# STM32F40x register map
File version: 1.5
Registers are 32-bit, read-write, reset 0x0 unless marked. A register's access mark holds for its fields unless they carry their own. Offsets are from the block's base; [hi:lo] are bit positions; {n}, {i} and the like mark numbered series; 'fields as' and 'values as' point back to an identical list.

## OTG_HS_HOST（USB_OTG_HS_主机寄存器） — USB OTG HS 主机寄存器（best-effort） | USB on the go high speed
Base 0x40040400
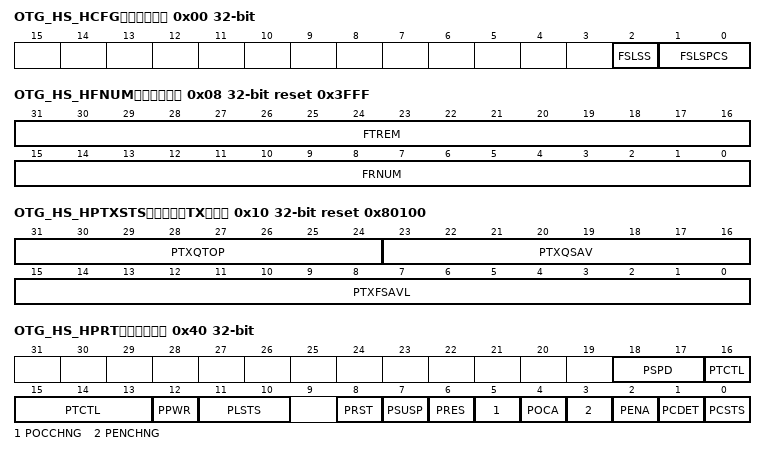
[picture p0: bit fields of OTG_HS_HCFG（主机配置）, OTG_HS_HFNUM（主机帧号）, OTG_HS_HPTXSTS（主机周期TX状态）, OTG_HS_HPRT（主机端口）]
0x00 OTG_HS_HCFG（主机配置） access per field — 主机配置 | OTG_HS host configuration register
  [2] FSLSS ro — FS- and LS-only support
  [1:0] FSLSPCS rw — FS/LS PHY clock select
0x04 OTG_HS_HFIR（主机帧间隔） reset 0xEA60 — 主机帧间隔 | OTG_HS Host frame interval register
  [15:0] FRIVL — Frame interval
0x08 OTG_HS_HFNUM（主机帧号） ro reset 0x3FFF — 主机帧编号 | OTG_HS host frame number/frame time remaining register
  [31:16] FTREM — Frame time remaining
  [15:0] FRNUM — Frame number
0x10 OTG_HS_HPTXSTS（主机周期TX状态） access per field reset 0x80100 — 主机周期发送状态 | OTG_HS_Host periodic transmit FIFO/queue status register
  [31:24] PTXQTOP ro — Top of the periodic transmit request queue
  [23:16] PTXQSAV ro — Periodic transmit request queue space available
  [15:0] PTXFSAVL rw — Periodic transmit data FIFO space available
0x14 OTG_HS_HAINT（主机通道中断） ro — 主机所有通道中断 | OTG_HS Host all channels interrupt register
  [15:0] HAINT — Channel interrupts
0x18 OTG_HS_HAINTMSK（主机通道中断屏蔽） — 主机通道中断屏蔽 | OTG_HS host all channels interrupt mask register
  [15:0] HAINTM — Channel interrupt mask
0x40 OTG_HS_HPRT（主机端口） access per field — 主机端口 | OTG_HS host port control and status register
  [18:17] PSPD ro — Port speed
  [16:13] PTCTL rw — Port test control
  [12] PPWR rw — Port power
  [11:10] PLSTS ro — Port line status
  [8] PRST rw — Port reset
  [7] PSUSP rw — Port suspend
  [6] PRES rw — Port resume
  [5] POCCHNG rw — Port overcurrent change
  [4] POCA ro — Port overcurrent active
  [3] PENCHNG rw — Port enable/disable change
  [2] PENA rw — Port enable
  [1] PCDET rw — Port connect detected
  [0] PCSTS ro — Port connect status
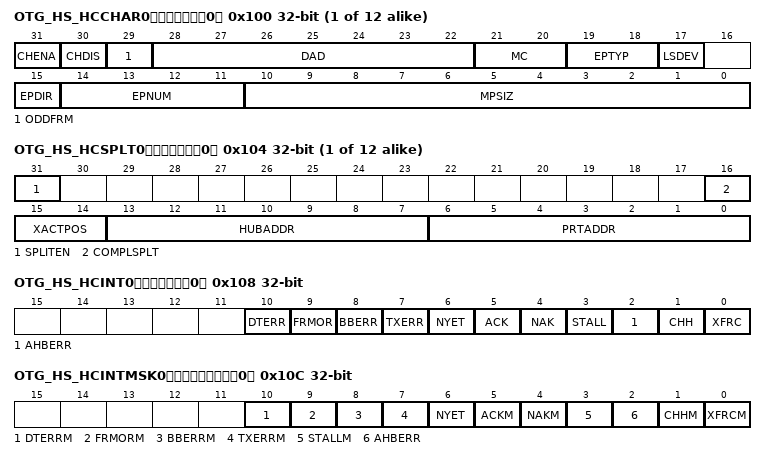
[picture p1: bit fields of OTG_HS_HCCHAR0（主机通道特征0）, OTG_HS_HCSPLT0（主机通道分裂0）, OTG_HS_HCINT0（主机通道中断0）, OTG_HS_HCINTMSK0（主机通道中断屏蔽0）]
{0x100+0x20*i} OTG_HS_HCCHAR{i}（主机通道特征{i}） (i=0..11) — USB OTG HS 主机通道特征{i} | OTG_HS host channel-{i} characteristics register
  [31] CHENA — Channel enable
  [30] CHDIS — Channel disable
  [29] ODDFRM — Odd frame
  [28:22] DAD — Device address
  [21:20] MC — Multi Count (MC) / Error Count (EC)
  [19:18] EPTYP — Endpoint type
  [17] LSDEV — Low-speed device
  [15] EPDIR — Endpoint direction
  [14:11] EPNUM — Endpoint number
  [10:0] MPSIZ — Maximum packet size
{0x104+0x20*i} OTG_HS_HCSPLT{i}（主机通道分裂{i}） (i=0..11) — USB OTG HS 主机通道分裂{i} | OTG_HS host channel-{i} split control register
  [31] SPLITEN — Split enable
  [16] COMPLSPLT — Do complete split
  [15:14] XACTPOS
  [13:7] HUBADDR — Hub address
  [6:0] PRTADDR — Port address
0x108 OTG_HS_HCINT0（主机通道中断0） — USB OTG HS 主机通道中断0 | OTG_HS host channel-11 interrupt register
  [10] DTERR — Data toggle error
  [9] FRMOR — Frame overrun
  [8] BBERR — Babble error
  [7] TXERR — Transaction error
  [6] NYET — Response received interrupt
  [5] ACK — ACK response received/transmitted interrupt
  [4] NAK — NAK response received interrupt
  [3] STALL — STALL response received interrupt
  [2] AHBERR — AHB error
  [1] CHH — Channel halted
  [0] XFRC — Transfer completed
0x10C OTG_HS_HCINTMSK0（主机通道中断屏蔽0） — USB OTG HS 主机通道中断屏蔽0 | OTG_HS host channel-11 interrupt mask register
  [10] DTERRM — Data toggle error mask
  [9] FRMORM — Frame overrun mask
  [8] BBERRM — Babble error mask
  [7] TXERRM — Transaction error mask
  [6] NYET — response received interrupt mask
  [5] ACKM — ACK response received/transmitted interrupt mask
  [4] NAKM — NAK response received interrupt mask
  [3] STALLM — STALL response received interrupt mask
  [2] AHBERR — AHB error
  [1] CHHM — Channel halted mask
  [0] XFRCM — Transfer completed mask
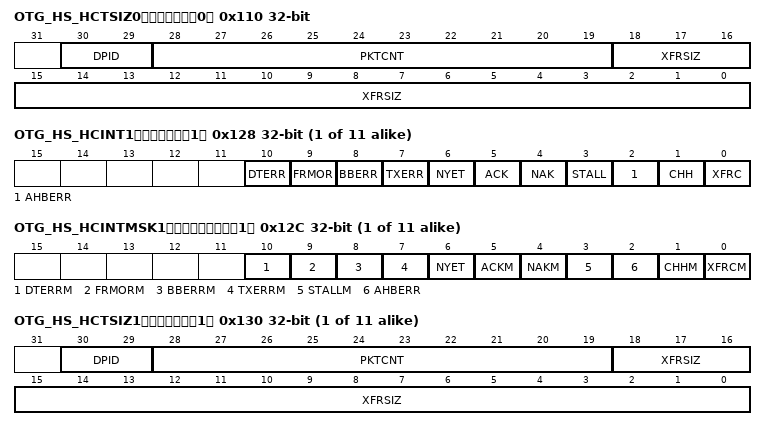
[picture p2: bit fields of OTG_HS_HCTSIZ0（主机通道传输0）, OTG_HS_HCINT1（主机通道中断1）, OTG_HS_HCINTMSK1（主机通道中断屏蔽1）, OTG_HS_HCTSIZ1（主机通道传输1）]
0x110 OTG_HS_HCTSIZ0（主机通道传输0） — USB OTG HS 主机通道传输0 | OTG_HS host channel-11 transfer size register
  [30:29] DPID — Data PID
  [28:19] PKTCNT — Packet count
  [18:0] XFRSIZ — Transfer size
{0x114+0x20*i} OTG_HS_HCDMA{i}（主机通道DMA{i}） (i=0..11) — USB OTG HS 主机通道DMA{i} | OTG_HS host channel-{i} DMA address register
  [31:0] DMAADDR — DMA address
{0x108+0x20*i} OTG_HS_HCINT{i}（主机通道中断{i}） (i=1..11) — USB OTG HS 主机通道中断{i} | OTG_HS host channel-{i} interrupt register
  fields as OTG_HS_HCINT0（主机通道中断0）
{0x10C+0x20*i} OTG_HS_HCINTMSK{i}（主机通道中断屏蔽{i}） (i=1..11) — USB OTG HS 主机通道中断屏蔽{i} | OTG_HS host channel-{i} interrupt mask register
  fields as OTG_HS_HCINTMSK0（主机通道中断屏蔽0）
{0x110+0x20*i} OTG_HS_HCTSIZ{i}（主机通道传输{i}） (i=1..11) — USB OTG HS 主机通道传输{i} | OTG_HS host channel-{i} transfer size register
  fields as OTG_HS_HCTSIZ0（主机通道传输0）
